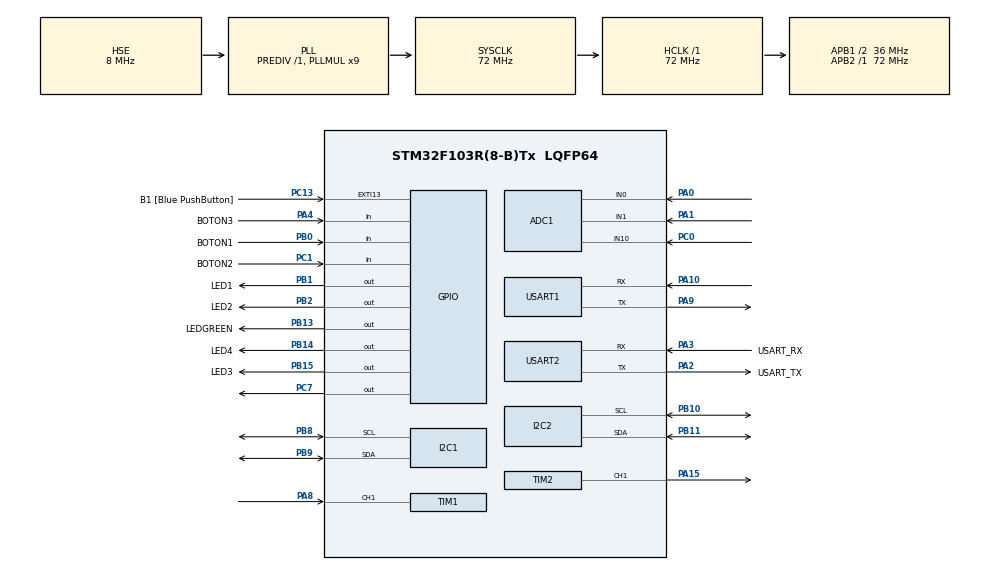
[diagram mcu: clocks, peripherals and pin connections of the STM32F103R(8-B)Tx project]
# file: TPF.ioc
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ADC1.Channel-1\#ChannelRegularConversion=ADC_CHANNEL_10
ADC1.Channel-2\#ChannelRegularConversion=ADC_CHANNEL_0
ADC1.Channel-3\#ChannelRegularConversion=ADC_CHANNEL_1
ADC1.ContinuousConvMode=ENABLE
ADC1.EnableInjectedConversion=ENABLE
ADC1.ExternalTrigConv=ADC_SOFTWARE_START
ADC1.NbrOfConversion=3
ADC1.NbrOfConversionFlag=1
ADC1.Rank-1\#ChannelRegularConversion=1
ADC1.Rank-2\#ChannelRegularConversion=2
ADC1.Rank-3\#ChannelRegularConversion=3
ADC1.SamplingTime-1\#ChannelRegularConversion=ADC_SAMPLETIME_239CYCLES_5
ADC1.SamplingTime-2\#ChannelRegularConversion=ADC_SAMPLETIME_239CYCLES_5
ADC1.SamplingTime-3\#ChannelRegularConversion=ADC_SAMPLETIME_239CYCLES_5
ADC1.master=1
Dma.ADC1.0.Direction=DMA_PERIPH_TO_MEMORY
Dma.ADC1.0.Instance=DMA1_Channel1
Dma.ADC1.0.MemDataAlignment=DMA_MDATAALIGN_WORD
Dma.ADC1.0.MemInc=DMA_MINC_ENABLE
Dma.ADC1.0.Mode=DMA_CIRCULAR
Dma.ADC1.0.PeriphDataAlignment=DMA_PDATAALIGN_WORD
Dma.ADC1.0.PeriphInc=DMA_PINC_DISABLE
Dma.ADC1.0.Priority=DMA_PRIORITY_LOW
Dma.Request0=ADC1
I2C1.DutyCycle=I2C_DUTYCYCLE_2
I2C1.I2C_Mode=I2C_Fast
I2C2.I2C_Mode=I2C_Fast
Mcu.Family=STM32F1
Mcu.Name=STM32F103R(8-B)Tx
Mcu.Package=LQFP64
NVIC.ADC1_2_IRQn=true\:0\:0\:false\:false\:true\:true\:true\:true
NVIC.DMA1_Channel1_IRQn=true\:0\:0\:false\:false\:true\:false\:true\:true
NVIC.EXTI15_10_IRQn=true\:0\:0\:false\:false\:true\:true\:true\:true
NVIC.I2C1_ER_IRQn=true\:0\:0\:false\:false\:true\:true\:true\:true
NVIC.I2C1_EV_IRQn=true\:0\:0\:false\:false\:true\:true\:true\:true
NVIC.I2C2_ER_IRQn=true\:0\:0\:false\:false\:true\:true\:true\:true
NVIC.I2C2_EV_IRQn=true\:0\:0\:false\:false\:true\:true\:true\:true
NVIC.PriorityGroup=NVIC_PRIORITYGROUP_4
NVIC.TIM1_CC_IRQn=true\:0\:0\:false\:false\:true\:true\:true\:true
PA0-WKUP.Signal=ADCx_IN0
PA1.Signal=ADCx_IN1
PA10.Mode=Asynchronous
PA10.Signal=USART1_RX
PA13.GPIO_Label=TMS
PA13.Mode=Serial_Wire
PA13.Signal=SYS_JTMS-SWDIO
PA14.GPIO_Label=TCK
PA14.Mode=Serial_Wire
PA14.Signal=SYS_JTCK-SWCLK
PA15.Signal=S_TIM2_CH1_ETR
PA2.GPIO_Label=USART_TX
PA2.GPIO_Mode=GPIO_MODE_AF_PP
PA2.GPIO_PuPd=GPIO_NOPULL
PA2.GPIO_Speed=GPIO_SPEED_FREQ_LOW
PA2.Mode=Asynchronous
PA2.Signal=USART2_TX
PA3.GPIO_Label=USART_RX
PA3.GPIO_Mode=GPIO_MODE_AF_PP
PA3.GPIO_PuPd=GPIO_NOPULL
PA3.GPIO_Speed=GPIO_SPEED_FREQ_LOW
PA3.Mode=Asynchronous
PA3.Signal=USART2_RX
PA4.GPIO_Label=BOTON3
PA4.GPIO_PuPd=GPIO_PULLDOWN
PA4.Signal=GPIO_Input
PA8.Signal=S_TIM1_CH1
PA9.Mode=Asynchronous
PA9.Signal=USART1_TX
PB0.GPIO_Label=BOTON1
PB0.GPIO_PuPd=GPIO_PULLDOWN
PB0.Signal=GPIO_Input
PB1.GPIO_Label=LED1
PB1.Signal=GPIO_Output
PB10.Mode=I2C
PB10.Signal=I2C2_SCL
PB11.Mode=I2C
PB11.Signal=I2C2_SDA
PB13.GPIO_Label=LEDGREEN
PB13.GPIO_ModeDefaultOutputPP=GPIO_MODE_OUTPUT_PP
PB13.GPIO_PuPd=GPIO_NOPULL
PB13.GPIO_Speed=GPIO_SPEED_FREQ_LOW
PB13.Signal=GPIO_Output
PB14.GPIO_Label=LED4
PB14.Signal=GPIO_Output
PB15.GPIO_Label=LED3
PB15.PinState=GPIO_PIN_RESET
PB15.Signal=GPIO_Output
PB2.GPIO_Label=LED2
PB2.Signal=GPIO_Output
PB3.GPIO_Label=SWO
PB3.Signal=SYS_JTDO-TRACESWO
PB8.Mode=I2C
PB8.Signal=I2C1_SCL
PB9.Mode=I2C
PB9.Signal=I2C1_SDA
PC0.Signal=ADCx_IN10
PC1.GPIO_Label=BOTON2
PC1.GPIO_PuPd=GPIO_PULLDOWN
PC1.Signal=GPIO_Input
PC13-TAMPER-RTC.GPIO_Label=B1 [Blue PushButton]
PC13-TAMPER-RTC.GPIO_PuPd=GPIO_NOPULL
PC13-TAMPER-RTC.Signal=GPXTI13
PC14-OSC32_IN.Signal=RCC_OSC32_IN
PC15-OSC32_OUT.Signal=RCC_OSC32_OUT
PC7.Signal=GPIO_Output
PD0-OSC_IN.Mode=HSE-External-Oscillator
PD0-OSC_IN.Signal=RCC_OSC_IN
PD1-OSC_OUT.Mode=HSE-External-Oscillator
PD1-OSC_OUT.Signal=RCC_OSC_OUT
ProjectManager.HeapSize=0x200
ProjectManager.StackSize=0x400
ProjectManager.TargetToolchain=STM32CubeIDE
RCC.ADCPresc=RCC_ADCPCLK2_DIV6
RCC.AHBFreq_Value=72000000
RCC.APB1CLKDivider=RCC_HCLK_DIV2
RCC.APB1Freq_Value=36000000
RCC.APB1TimFreq_Value=72000000
RCC.APB2Freq_Value=72000000
RCC.APB2TimFreq_Value=72000000
RCC.HCLKFreq_Value=72000000
RCC.PLLMUL=RCC_PLL_MUL9
RCC.PLLSourceVirtual=RCC_PLLSOURCE_HSE
RCC.RTCClockSelection=RCC_RTCCLKSOURCE_LSE
RCC.SYSCLKFreq_VALUE=72000000
RCC.SYSCLKSource=RCC_SYSCLKSOURCE_PLLCLK
RCC.USBFreq_Value=72000000
SH.ADCx_IN0.0=ADC1_IN0,IN0
SH.ADCx_IN1.0=ADC1_IN1,IN1
SH.ADCx_IN10.0=ADC1_IN10,IN10
SH.S_TIM1_CH1.0=TIM1_CH1,Input_Capture1_from_TI1
SH.S_TIM2_CH1_ETR.0=TIM2_CH1,Output Compare1 CH1
TIM1.Channel-Input_Capture1_from_TI1=TIM_CHANNEL_1
TIM1.Prescaler=72
TIM2.Channel-Output\ Compare1\ CH1=TIM_CHANNEL_1
USART1.VirtualMode=VM_ASYNC
USART2.VirtualMode=VM_ASYNC
board=NUCLEO-F103RB

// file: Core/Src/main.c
/* USER CODE BEGIN Header */
/**
  ******************************************************************************
  * @file           : main.c
  * @brief          : Main program body
  ******************************************************************************
  * @attention
  *
  * Copyright (c) 2025 STMicroelectronics.
  * All rights reserved.
  *
  * This software is licensed under terms that can be found in the LICENSE file
  * in the root directory of this software component.
  * If no LICENSE file comes with this software, it is provided AS-IS.
  *
  ******************************************************************************
  */
/* USER CODE END Header */
#include "main.h"

/* USER CODE BEGIN Includes */
#include "app.h"
#include <stdio.h>
#include "logger.h"
#include "dwt.h"

/* USER CODE END Includes */

ADC_HandleTypeDef hadc1;
DMA_HandleTypeDef hdma_adc1;

I2C_HandleTypeDef hi2c1;
I2C_HandleTypeDef hi2c2;

TIM_HandleTypeDef htim1;
TIM_HandleTypeDef htim2;

UART_HandleTypeDef huart1;
UART_HandleTypeDef huart2;

void SystemClock_Config(void);
static void MX_GPIO_Init(void);
static void MX_DMA_Init(void);
static void MX_USART2_UART_Init(void);
static void MX_I2C1_Init(void);
static void MX_ADC1_Init(void);
static void MX_I2C2_Init(void);
static void MX_USART1_UART_Init(void);
static void MX_TIM1_Init(void);
static void MX_TIM2_Init(void);

/* USER CODE BEGIN 0 */
#if (1 == LOGGER_CONFIG_USE_SEMIHOSTING)

extern void initialise_monitor_handles(void);

#endif

/* USER CODE END 0 */

int main(void)
{

  /* USER CODE BEGIN 1 */

#if (1 == LOGGER_CONFIG_USE_SEMIHOSTING)

initialise_monitor_handles();

#endif

  /* USER CODE END 1 */

  /* MCU Configuration--------------------------------------------------------*/

  /* Reset of all peripherals, Initializes the Flash interface and the Systick. */
  HAL_Init();

  /* Configure the system clock */
  SystemClock_Config();

  /* Initialize all configured peripherals */
  MX_GPIO_Init();
  MX_DMA_Init();
  MX_USART2_UART_Init();
  MX_I2C1_Init();
  MX_ADC1_Init();
  MX_I2C2_Init();
  MX_USART1_UART_Init();
  MX_TIM1_Init();
  MX_TIM2_Init();
  /* USER CODE BEGIN 2 */
  app_init();
  /* USER CODE END 2 */

  /* Infinite loop */
  while (1)
  {
	  app_update();
  }
}

void SystemClock_Config(void)
{
  RCC_OscInitTypeDef RCC_OscInitStruct = {0};
  RCC_ClkInitTypeDef RCC_ClkInitStruct = {0};
  RCC_PeriphCLKInitTypeDef PeriphClkInit = {0};

  /** Initializes the RCC Oscillators according to the specified parameters
  * in the RCC_OscInitTypeDef structure.
  */
  RCC_OscInitStruct.OscillatorType = RCC_OSCILLATORTYPE_HSE;
  RCC_OscInitStruct.HSEState = RCC_HSE_ON;
  RCC_OscInitStruct.HSEPredivValue = RCC_HSE_PREDIV_DIV1;
  RCC_OscInitStruct.HSIState = RCC_HSI_ON;
  RCC_OscInitStruct.PLL.PLLState = RCC_PLL_ON;
  RCC_OscInitStruct.PLL.PLLSource = RCC_PLLSOURCE_HSE;
  RCC_OscInitStruct.PLL.PLLMUL = RCC_PLL_MUL9;
  if (HAL_RCC_OscConfig(&RCC_OscInitStruct) != HAL_OK)
  {
    Error_Handler();
  }

  /** Initializes the CPU, AHB and APB buses clocks
  */
  RCC_ClkInitStruct.ClockType = RCC_CLOCKTYPE_HCLK|RCC_CLOCKTYPE_SYSCLK
                              |RCC_CLOCKTYPE_PCLK1|RCC_CLOCKTYPE_PCLK2;
  RCC_ClkInitStruct.SYSCLKSource = RCC_SYSCLKSOURCE_PLLCLK;
  RCC_ClkInitStruct.AHBCLKDivider = RCC_SYSCLK_DIV1;
  RCC_ClkInitStruct.APB1CLKDivider = RCC_HCLK_DIV2;
  RCC_ClkInitStruct.APB2CLKDivider = RCC_HCLK_DIV1;

  if (HAL_RCC_ClockConfig(&RCC_ClkInitStruct, FLASH_LATENCY_2) != HAL_OK)
  {
    Error_Handler();
  }
  PeriphClkInit.PeriphClockSelection = RCC_PERIPHCLK_ADC;
  PeriphClkInit.AdcClockSelection = RCC_ADCPCLK2_DIV6;
  if (HAL_RCCEx_PeriphCLKConfig(&PeriphClkInit) != HAL_OK)
  {
    Error_Handler();
  }
}

static void MX_ADC1_Init(void)
{

  ADC_ChannelConfTypeDef sConfig = {0};

  /** Common config
  */
  hadc1.Instance = ADC1;
  hadc1.Init.ScanConvMode = ADC_SCAN_ENABLE;
  hadc1.Init.ContinuousConvMode = ENABLE;
  hadc1.Init.DiscontinuousConvMode = DISABLE;
  hadc1.Init.ExternalTrigConv = ADC_SOFTWARE_START;
  hadc1.Init.DataAlign = ADC_DATAALIGN_RIGHT;
  hadc1.Init.NbrOfConversion = 3;
  if (HAL_ADC_Init(&hadc1) != HAL_OK)
  {
    Error_Handler();
  }

  /** Configure Regular Channel
  */
  sConfig.Channel = ADC_CHANNEL_10;
  sConfig.Rank = ADC_REGULAR_RANK_1;
  sConfig.SamplingTime = ADC_SAMPLETIME_239CYCLES_5;
  if (HAL_ADC_ConfigChannel(&hadc1, &sConfig) != HAL_OK)
  {
    Error_Handler();
  }

  /** Configure Regular Channel
  */
  sConfig.Channel = ADC_CHANNEL_0;
  sConfig.Rank = ADC_REGULAR_RANK_2;
  if (HAL_ADC_ConfigChannel(&hadc1, &sConfig) != HAL_OK)
  {
    Error_Handler();
  }

  /** Configure Regular Channel
  */
  sConfig.Channel = ADC_CHANNEL_1;
  sConfig.Rank = ADC_REGULAR_RANK_3;
  if (HAL_ADC_ConfigChannel(&hadc1, &sConfig) != HAL_OK)
  {
    Error_Handler();
  }

}

static void MX_I2C1_Init(void)
{

  hi2c1.Instance = I2C1;
  hi2c1.Init.ClockSpeed = 400000;
  hi2c1.Init.DutyCycle = I2C_DUTYCYCLE_2;
  hi2c1.Init.OwnAddress1 = 0;
  hi2c1.Init.AddressingMode = I2C_ADDRESSINGMODE_7BIT;
  hi2c1.Init.DualAddressMode = I2C_DUALADDRESS_DISABLE;
  hi2c1.Init.OwnAddress2 = 0;
  hi2c1.Init.GeneralCallMode = I2C_GENERALCALL_DISABLE;
  hi2c1.Init.NoStretchMode = I2C_NOSTRETCH_DISABLE;
  if (HAL_I2C_Init(&hi2c1) != HAL_OK)
  {
    Error_Handler();
  }

}

static void MX_I2C2_Init(void)
{

  hi2c2.Instance = I2C2;
  hi2c2.Init.ClockSpeed = 400000;
  hi2c2.Init.DutyCycle = I2C_DUTYCYCLE_2;
  hi2c2.Init.OwnAddress1 = 0;
  hi2c2.Init.AddressingMode = I2C_ADDRESSINGMODE_7BIT;
  hi2c2.Init.DualAddressMode = I2C_DUALADDRESS_DISABLE;
  hi2c2.Init.OwnAddress2 = 0;
  hi2c2.Init.GeneralCallMode = I2C_GENERALCALL_DISABLE;
  hi2c2.Init.NoStretchMode = I2C_NOSTRETCH_DISABLE;
  if (HAL_I2C_Init(&hi2c2) != HAL_OK)
  {
    Error_Handler();
  }

}

static void MX_TIM1_Init(void)
{

  TIM_MasterConfigTypeDef sMasterConfig = {0};
  TIM_IC_InitTypeDef sConfigIC = {0};

  htim1.Instance = TIM1;
  htim1.Init.Prescaler = 72;
  htim1.Init.CounterMode = TIM_COUNTERMODE_UP;
  htim1.Init.Period = 65535;
  htim1.Init.ClockDivision = TIM_CLOCKDIVISION_DIV1;
  htim1.Init.RepetitionCounter = 0;
  htim1.Init.AutoReloadPreload = TIM_AUTORELOAD_PRELOAD_DISABLE;
  if (HAL_TIM_IC_Init(&htim1) != HAL_OK)
  {
    Error_Handler();
  }
  sMasterConfig.MasterOutputTrigger = TIM_TRGO_RESET;
  sMasterConfig.MasterSlaveMode = TIM_MASTERSLAVEMODE_DISABLE;
  if (HAL_TIMEx_MasterConfigSynchronization(&htim1, &sMasterConfig) != HAL_OK)
  {
    Error_Handler();
  }
  sConfigIC.ICPolarity = TIM_INPUTCHANNELPOLARITY_RISING;
  sConfigIC.ICSelection = TIM_ICSELECTION_DIRECTTI;
  sConfigIC.ICPrescaler = TIM_ICPSC_DIV1;
  sConfigIC.ICFilter = 0;
  if (HAL_TIM_IC_ConfigChannel(&htim1, &sConfigIC, TIM_CHANNEL_1) != HAL_OK)
  {
    Error_Handler();
  }

}

static void MX_TIM2_Init(void)
{

  TIM_MasterConfigTypeDef sMasterConfig = {0};
  TIM_OC_InitTypeDef sConfigOC = {0};

  htim2.Instance = TIM2;
  htim2.Init.Prescaler = 0;
  htim2.Init.CounterMode = TIM_COUNTERMODE_UP;
  htim2.Init.Period = 65535;
  htim2.Init.ClockDivision = TIM_CLOCKDIVISION_DIV1;
  htim2.Init.AutoReloadPreload = TIM_AUTORELOAD_PRELOAD_DISABLE;
  if (HAL_TIM_OC_Init(&htim2) != HAL_OK)
  {
    Error_Handler();
  }
  sMasterConfig.MasterOutputTrigger = TIM_TRGO_RESET;
  sMasterConfig.MasterSlaveMode = TIM_MASTERSLAVEMODE_DISABLE;
  if (HAL_TIMEx_MasterConfigSynchronization(&htim2, &sMasterConfig) != HAL_OK)
  {
    Error_Handler();
  }
  sConfigOC.OCMode = TIM_OCMODE_TIMING;
  sConfigOC.Pulse = 0;
  sConfigOC.OCPolarity = TIM_OCPOLARITY_HIGH;
  sConfigOC.OCFastMode = TIM_OCFAST_DISABLE;
  if (HAL_TIM_OC_ConfigChannel(&htim2, &sConfigOC, TIM_CHANNEL_1) != HAL_OK)
  {
    Error_Handler();
  }
  HAL_TIM_MspPostInit(&htim2);

}

static void MX_USART1_UART_Init(void)
{

  huart1.Instance = USART1;
  huart1.Init.BaudRate = 115200;
  huart1.Init.WordLength = UART_WORDLENGTH_8B;
  huart1.Init.StopBits = UART_STOPBITS_1;
  huart1.Init.Parity = UART_PARITY_NONE;
  huart1.Init.Mode = UART_MODE_TX_RX;
  huart1.Init.HwFlowCtl = UART_HWCONTROL_NONE;
  huart1.Init.OverSampling = UART_OVERSAMPLING_16;
  if (HAL_UART_Init(&huart1) != HAL_OK)
  {
    Error_Handler();
  }

}

static void MX_USART2_UART_Init(void)
{

  huart2.Instance = USART2;
  huart2.Init.BaudRate = 115200;
  huart2.Init.WordLength = UART_WORDLENGTH_8B;
  huart2.Init.StopBits = UART_STOPBITS_1;
  huart2.Init.Parity = UART_PARITY_NONE;
  huart2.Init.Mode = UART_MODE_TX_RX;
  huart2.Init.HwFlowCtl = UART_HWCONTROL_NONE;
  huart2.Init.OverSampling = UART_OVERSAMPLING_16;
  if (HAL_UART_Init(&huart2) != HAL_OK)
  {
    Error_Handler();
  }

}

static void MX_DMA_Init(void)
{

  /* DMA controller clock enable */
  __HAL_RCC_DMA1_CLK_ENABLE();

  /* DMA interrupt init */
  /* DMA1_Channel1_IRQn interrupt configuration */
  HAL_NVIC_SetPriority(DMA1_Channel1_IRQn, 0, 0);
  HAL_NVIC_EnableIRQ(DMA1_Channel1_IRQn);

}

static void MX_GPIO_Init(void)
{
  GPIO_InitTypeDef GPIO_InitStruct = {0};

  /* GPIO Ports Clock Enable */
  __HAL_RCC_GPIOC_CLK_ENABLE();
  __HAL_RCC_GPIOD_CLK_ENABLE();
  __HAL_RCC_GPIOA_CLK_ENABLE();
  __HAL_RCC_GPIOB_CLK_ENABLE();

  /*Configure GPIO pin Output Level */
  HAL_GPIO_WritePin(GPIOB, LED1_Pin|LED2_Pin|LEDGREEN_Pin|LED4_Pin
                          |LED3_Pin, GPIO_PIN_RESET);

  /*Configure GPIO pin Output Level */
  HAL_GPIO_WritePin(GPIOC, GPIO_PIN_7, GPIO_PIN_RESET);

  /*Configure GPIO pin : B1_Pin */
  GPIO_InitStruct.Pin = B1_Pin;
  GPIO_InitStruct.Mode = GPIO_MODE_IT_RISING;
  GPIO_InitStruct.Pull = GPIO_NOPULL;
  HAL_GPIO_Init(B1_GPIO_Port, &GPIO_InitStruct);

  /*Configure GPIO pin : BOTON2_Pin */
  GPIO_InitStruct.Pin = BOTON2_Pin;
  GPIO_InitStruct.Mode = GPIO_MODE_INPUT;
  GPIO_InitStruct.Pull = GPIO_PULLDOWN;
  HAL_GPIO_Init(BOTON2_GPIO_Port, &GPIO_InitStruct);

  /*Configure GPIO pin : BOTON3_Pin */
  GPIO_InitStruct.Pin = BOTON3_Pin;
  GPIO_InitStruct.Mode = GPIO_MODE_INPUT;
  GPIO_InitStruct.Pull = GPIO_PULLDOWN;
  HAL_GPIO_Init(BOTON3_GPIO_Port, &GPIO_InitStruct);

  /*Configure GPIO pin : BOTON1_Pin */
  GPIO_InitStruct.Pin = BOTON1_Pin;
  GPIO_InitStruct.Mode = GPIO_MODE_INPUT;
  GPIO_InitStruct.Pull = GPIO_PULLDOWN;
  HAL_GPIO_Init(BOTON1_GPIO_Port, &GPIO_InitStruct);

  /*Configure GPIO pins : LED1_Pin LED2_Pin LEDGREEN_Pin LED4_Pin
                           LED3_Pin */
  GPIO_InitStruct.Pin = LED1_Pin|LED2_Pin|LEDGREEN_Pin|LED4_Pin
                          |LED3_Pin;
  GPIO_InitStruct.Mode = GPIO_MODE_OUTPUT_PP;
  GPIO_InitStruct.Pull = GPIO_NOPULL;
  GPIO_InitStruct.Speed = GPIO_SPEED_FREQ_LOW;
  HAL_GPIO_Init(GPIOB, &GPIO_InitStruct);

  /*Configure GPIO pin : PC7 */
  GPIO_InitStruct.Pin = GPIO_PIN_7;
  GPIO_InitStruct.Mode = GPIO_MODE_OUTPUT_PP;
  GPIO_InitStruct.Pull = GPIO_NOPULL;
  GPIO_InitStruct.Speed = GPIO_SPEED_FREQ_LOW;
  HAL_GPIO_Init(GPIOC, &GPIO_InitStruct);

  /* EXTI interrupt init*/
  HAL_NVIC_SetPriority(EXTI15_10_IRQn, 0, 0);
  HAL_NVIC_EnableIRQ(EXTI15_10_IRQn);

}

/* USER CODE BEGIN 4 */
//void delay_ms(uint16_t delay){

	//__HAL_TIM_SET_COUNTER(&htim2, 0);
	//timer_ms = __HAL_TIM_GET_COUNTER(&htim2);
//	while(timer_ms < delay){
	//	timer_ms = __HAL_TIM_GET_COUNTER(&htim2);
	//}
//}
/* USER CODE END 4 */

void Error_Handler(void)
{
  __disable_irq();
  while (1)
  {
  }
}
